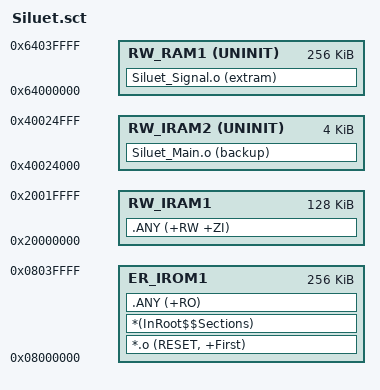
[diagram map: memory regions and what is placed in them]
; *************************************************************
; *** Scatter-Loading Description File generated by uVision ***
; *************************************************************

LR_IROM1 0x08000000 0x00040000  {    ; load region size_region
  ER_IROM1 0x08000000 0x00040000  {  ; load address = execution address
   *.o (RESET, +First)
   *(InRoot$$Sections)
   .ANY (+RO)
  }
  RW_IRAM1 0x20000000 0x00020000  {
   .ANY (+RW +ZI)
  }
  RW_IRAM2 0x40024000 UNINIT 0x00001000 {	; Backup RAM
    Siluet_Main.o (backup)
  }
  
  RW_RAM1 0x64000000 UNINIT 0x00040000  {	; RW data
   Siluet_Signal.o (extram)
  }
  
}

